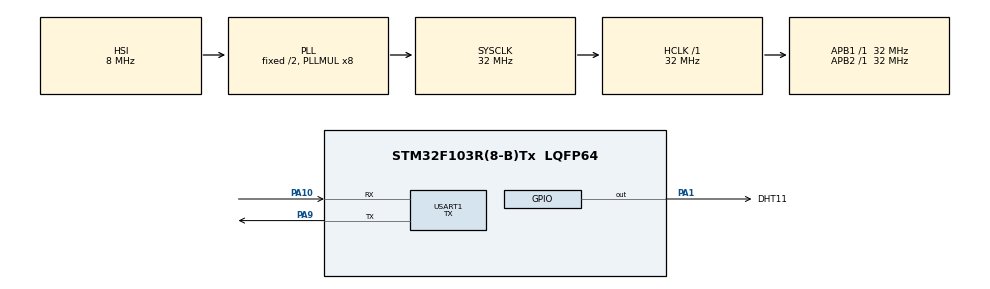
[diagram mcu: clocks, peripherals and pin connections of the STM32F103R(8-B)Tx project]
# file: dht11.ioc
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Mcu.Family=STM32F1
Mcu.Name=STM32F103R(8-B)Tx
Mcu.Package=LQFP64
NVIC.PriorityGroup=NVIC_PRIORITYGROUP_4
PA1.GPIO_Label=DHT11
PA1.GPIO_PuPd=GPIO_PULLUP
PA1.Signal=GPIO_Output
PA10.Mode=Asynchronous
PA10.Signal=USART1_RX
PA13.Mode=Serial_Wire
PA13.Signal=SYS_JTMS-SWDIO
PA14.Mode=Serial_Wire
PA14.Signal=SYS_JTCK-SWCLK
PA9.Mode=Asynchronous
PA9.Signal=USART1_TX
ProjectManager.HeapSize=0x200
ProjectManager.StackSize=0x400
ProjectManager.TargetToolchain=Makefile
RCC.AHBFreq_Value=32000000
RCC.APB1Freq_Value=32000000
RCC.APB1TimFreq_Value=32000000
RCC.APB2Freq_Value=32000000
RCC.APB2TimFreq_Value=32000000
RCC.HCLKFreq_Value=32000000
RCC.PLLMUL=RCC_PLL_MUL8
RCC.SYSCLKFreq_VALUE=32000000
RCC.SYSCLKSource=RCC_SYSCLKSOURCE_PLLCLK
RCC.USBFreq_Value=32000000
TIM3.AutoReloadPreload=TIM_AUTORELOAD_PRELOAD_ENABLE
TIM3.Period=65535
TIM3.Prescaler=32-1
USART1.Mode=MODE_TX
USART1.VirtualMode=VM_ASYNC
VP_TIM3_VS_ClockSourceINT.Mode=Internal
board=custom

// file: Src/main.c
/* USER CODE BEGIN Header */
/**
  ******************************************************************************
  * @file           : main.c
  * @brief          : Main program body
  ******************************************************************************
  * @attention
  *
  * Copyright (c) 2024 STMicroelectronics.
  * All rights reserved.
  *
  * This software is licensed under terms that can be found in the LICENSE file
  * in the root directory of this software component.
  * If no LICENSE file comes with this software, it is provided AS-IS.
  *
  ******************************************************************************
  */
/* USER CODE END Header */
#include "main.h"
#include "tim.h"
#include "usart.h"
#include "gpio.h"

/* USER CODE BEGIN Includes */
#include "dht11.h"
/* USER CODE END Includes */

void SystemClock_Config(void);

int main(void)
{

  /* MCU Configuration--------------------------------------------------------*/

  /* Reset of all peripherals, Initializes the Flash interface and the Systick. */
  HAL_Init();

  /* Configure the system clock */
  SystemClock_Config();

  /* Initialize all configured peripherals */
  MX_GPIO_Init();
  MX_TIM3_Init();
  MX_USART1_UART_Init();
  initLed();
  /* USER CODE BEGIN 2 */
  uint8_t gtemperature = 0;
  uint8_t ghumidity = 0;

  //HAL_GPIO_WritePin(GPIOA, GPIO_PIN_5, GPIO_PIN_SET);
  /* USER CODE END 2 */

  /* Infinite loop */
  /* USER CODE BEGIN WHILE */
  while (1)
  {
    LL_GPIO_TogglePin(GPIOA, LL_GPIO_PIN_5);
    if (DHTRead(&ghumidity, &gtemperature) == 0)
    {
      sendToUart(&ghumidity, &gtemperature);
    }
        LL_mDelay(1000);
    /* USER CODE END WHILE */

  }
}

void SystemClock_Config(void)
{
  RCC_OscInitTypeDef RCC_OscInitStruct = {0};
  RCC_ClkInitTypeDef RCC_ClkInitStruct = {0};

  /** Initializes the RCC Oscillators according to the specified parameters
  * in the RCC_OscInitTypeDef structure.
  */
  RCC_OscInitStruct.OscillatorType = RCC_OSCILLATORTYPE_HSI;
  RCC_OscInitStruct.HSIState = RCC_HSI_ON;
  RCC_OscInitStruct.HSICalibrationValue = RCC_HSICALIBRATION_DEFAULT;
  RCC_OscInitStruct.PLL.PLLState = RCC_PLL_ON;
  RCC_OscInitStruct.PLL.PLLSource = RCC_PLLSOURCE_HSI_DIV2;
  RCC_OscInitStruct.PLL.PLLMUL = RCC_PLL_MUL8;
  if (HAL_RCC_OscConfig(&RCC_OscInitStruct) != HAL_OK)
  {
    Error_Handler();
  }

  /** Initializes the CPU, AHB and APB buses clocks
  */
  RCC_ClkInitStruct.ClockType = RCC_CLOCKTYPE_HCLK|RCC_CLOCKTYPE_SYSCLK
                              |RCC_CLOCKTYPE_PCLK1|RCC_CLOCKTYPE_PCLK2;
  RCC_ClkInitStruct.SYSCLKSource = RCC_SYSCLKSOURCE_PLLCLK;
  RCC_ClkInitStruct.AHBCLKDivider = RCC_SYSCLK_DIV1;
  RCC_ClkInitStruct.APB1CLKDivider = RCC_HCLK_DIV1;
  RCC_ClkInitStruct.APB2CLKDivider = RCC_HCLK_DIV1;

  if (HAL_RCC_ClockConfig(&RCC_ClkInitStruct, FLASH_LATENCY_1) != HAL_OK)
  {
    Error_Handler();
  }
}

void Error_Handler(void)
{
  __disable_irq();
  while (1)
  {
  }
}
